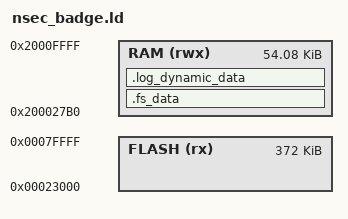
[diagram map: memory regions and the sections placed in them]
/* Linker script to configure memory regions. */

SEARCH_DIR(.)
GROUP(-lgcc -lc -lnosys)

MEMORY
{
  FLASH (rx) : ORIGIN = 0x23000, LENGTH = 0x5d000
  /* 0x200027B0 as returned by nrf_sdh_ble_default_cfg_set */
  RAM (rwx) :  ORIGIN = 0x200027B0, LENGTH = 0xD850
}

SECTIONS
{
  .fs_data :
  {
    PROVIDE(__start_fs_data = .);
    KEEP(*(.fs_data))
    PROVIDE(__stop_fs_data = .);
  } > RAM
  .log_dynamic_data :
  {
    PROVIDE(__start_log_dynamic_data = .);
    KEEP(*(SORT(.log_dynamic_data*)))
    PROVIDE(__stop_log_dynamic_data = .);
  } > RAM
} INSERT AFTER .data;

/* I have no idea what it does, but without that the softdevice doesn't compile, I'll check that later.*/
SECTIONS
{
  .mem_section_dummy_rom :
  {
  }
  .sdh_soc_observers :
  {
    PROVIDE(__start_sdh_soc_observers = .);
    KEEP(*(SORT(.sdh_soc_observers*)))
    PROVIDE(__stop_sdh_soc_observers = .);
  } > FLASH
  .sdh_ble_observers :
  {
    PROVIDE(__start_sdh_ble_observers = .);
    KEEP(*(SORT(.sdh_ble_observers*)))
    PROVIDE(__stop_sdh_ble_observers = .);
  } > FLASH
  .sdh_req_observers :
  {
    PROVIDE(__start_sdh_req_observers = .);
    KEEP(*(SORT(.sdh_req_observers*)))
    PROVIDE(__stop_sdh_req_observers = .);
  } > FLASH
  .sdh_state_observers :
  {
    PROVIDE(__start_sdh_state_observers = .);
    KEEP(*(SORT(.sdh_state_observers*)))
    PROVIDE(__stop_sdh_state_observers = .);
  } > FLASH
  .sdh_stack_observers :
  {
    PROVIDE(__start_sdh_stack_observers = .);
    KEEP(*(SORT(.sdh_stack_observers*)))
    PROVIDE(__stop_sdh_stack_observers = .);
  } > FLASH
  .log_const_data :
  {
    PROVIDE(__start_log_const_data = .);
    KEEP(*(SORT(.log_const_data*)))
    PROVIDE(__stop_log_const_data = .);
  } > FLASH
} INSERT AFTER .text

INCLUDE "nrf5x_common.ld"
